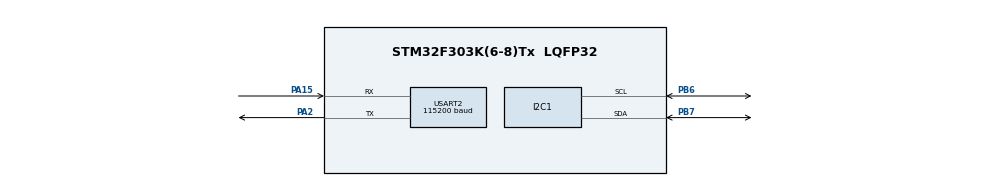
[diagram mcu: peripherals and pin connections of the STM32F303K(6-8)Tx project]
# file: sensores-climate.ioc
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Dma.Request0=USART2_RX
Dma.Request1=USART2_TX
Dma.USART2_RX.0.Direction=DMA_PERIPH_TO_MEMORY
Dma.USART2_RX.0.Instance=DMA1_Channel6
Dma.USART2_RX.0.MemDataAlignment=DMA_MDATAALIGN_BYTE
Dma.USART2_RX.0.MemInc=DMA_MINC_ENABLE
Dma.USART2_RX.0.Mode=DMA_NORMAL
Dma.USART2_RX.0.PeriphDataAlignment=DMA_PDATAALIGN_BYTE
Dma.USART2_RX.0.PeriphInc=DMA_PINC_DISABLE
Dma.USART2_RX.0.Priority=DMA_PRIORITY_MEDIUM
Dma.USART2_TX.1.Direction=DMA_MEMORY_TO_PERIPH
Dma.USART2_TX.1.Instance=DMA1_Channel7
Dma.USART2_TX.1.MemDataAlignment=DMA_MDATAALIGN_BYTE
Dma.USART2_TX.1.MemInc=DMA_MINC_ENABLE
Dma.USART2_TX.1.Mode=DMA_NORMAL
Dma.USART2_TX.1.PeriphDataAlignment=DMA_PDATAALIGN_BYTE
Dma.USART2_TX.1.PeriphInc=DMA_PINC_DISABLE
Dma.USART2_TX.1.Priority=DMA_PRIORITY_MEDIUM
I2C1.Timing=0x00201D2B
Mcu.Family=STM32F3
Mcu.Name=STM32F303K(6-8)Tx
Mcu.Package=LQFP32
NVIC.DMA1_Channel6_IRQn=true\:0\:0\:false\:false\:true\:false\:true\:true
NVIC.DMA1_Channel7_IRQn=true\:0\:0\:false\:false\:true\:false\:true\:true
NVIC.I2C1_EV_IRQn=true\:0\:0\:false\:false\:true\:true\:true\:true
NVIC.PriorityGroup=NVIC_PRIORITYGROUP_4
PA13.Mode=Serial_Wire
PA13.Signal=SYS_JTMS-SWDIO
PA14.Mode=Serial_Wire
PA14.Signal=SYS_JTCK-SWCLK
PA15.Mode=Asynchronous
PA15.Signal=USART2_RX
PA2.Mode=Asynchronous
PA2.Signal=USART2_TX
PB6.Mode=I2C
PB6.Signal=I2C1_SCL
PB7.Mode=I2C
PB7.Signal=I2C1_SDA
ProjectManager.HeapSize=0x200
ProjectManager.StackSize=0x400
ProjectManager.TargetToolchain=STM32CubeIDE
RCC.AHBFreq_Value=8000000
RCC.APB1Freq_Value=8000000
RCC.APB2Freq_Value=8000000
RCC.CortexFreq_Value=8000000
RCC.HSE_VALUE=8000000
RCC.HSI_VALUE=8000000
RCC.SYSCLKFreq_VALUE=8000000
USART2.BaudRate=115200
USART2.VirtualMode-Asynchronous=VM_ASYNC
board=custom

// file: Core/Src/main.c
/* USER CODE BEGIN Header */
/**
  ******************************************************************************
  * @file           : main.c
  * @brief          : Main program body
  ******************************************************************************
  * @attention
  *
  * Copyright (c) 2024 STMicroelectronics.
  * All rights reserved.
  *
  * This software is licensed under terms that can be found in the LICENSE file
  * in the root directory of this software component.
  * If no LICENSE file comes with this software, it is provided AS-IS.
  *
  ******************************************************************************
  */
/* USER CODE END Header */
#include "main.h"
#include "dma.h"
#include "i2c.h"
#include "usart.h"
#include "gpio.h"
#include "HTS221.h"
#include "LPS25HB.h"

/* USER CODE BEGIN PV */
float temperature;
float humidity;
float pressure;
float refference_pressure;
/* USER CODE END PV */

void SystemClock_Config(void);

#include <math.h>

#define SEA_LEVEL_PRESSURE 101325 // Pa, standard sea level pressure

// Function to calculate altitude based on pressure
float calculateAltitude(float pressure) {
    return (44330.0 * (1.0 - pow((pressure / SEA_LEVEL_PRESSURE), 0.1903)));
}

int main(void)
{

  /* MCU Configuration--------------------------------------------------------*/

  /* Reset of all peripherals, Initializes the Flash interface and the Systick. */
  LL_APB2_GRP1_EnableClock(LL_APB2_GRP1_PERIPH_SYSCFG);
  LL_APB1_GRP1_EnableClock(LL_APB1_GRP1_PERIPH_PWR);

  /* System interrupt init*/
  NVIC_SetPriorityGrouping(NVIC_PRIORITYGROUP_4);

  /* SysTick_IRQn interrupt configuration */
  NVIC_SetPriority(SysTick_IRQn, NVIC_EncodePriority(NVIC_GetPriorityGrouping(),15, 0));

  /* Configure the system clock */
  SystemClock_Config();

  /* Initialize all configured peripherals */
  MX_GPIO_Init();
  MX_DMA_Init();
  MX_I2C1_Init();
  MX_USART2_UART_Init();
  /* USER CODE BEGIN 2 */

  HTS221_init();
  LPS25HB_init();

  char tx_data[120];
  const char tx_message[] = "Temperature: %2.1f°C, Humidity: %.0f%%, Altitude: %.2f m, Pressure: %.2f Pa\r\n";
  //uint8_t tx_data[120];
  LL_mDelay(10);
  LPS25HB_get_pressure(&refference_pressure); // Reference pressure at the start for altitude comparison

  while (1) {
          HTS221_get_temperature(&temperature);
          HTS221_get_humidity(&humidity);
          LPS25HB_get_pressure(&pressure);
          float altitude = 44330.0 * (1.0 - pow(pressure / refference_pressure, 1 / 5.255));
          uint8_t tx_data_len = (uint8_t)sprintf(tx_data, tx_message, temperature, humidity, altitude, pressure);
          USART2_PutBuffer((uint8_t*)tx_data, tx_data_len);
          LL_mDelay(500);
      }

  /* USER CODE END 3 */
}

void SystemClock_Config(void)
{
  LL_FLASH_SetLatency(LL_FLASH_LATENCY_0);
  while(LL_FLASH_GetLatency()!= LL_FLASH_LATENCY_0)
  {
  }
  LL_RCC_HSI_Enable();

   /* Wait till HSI is ready */
  while(LL_RCC_HSI_IsReady() != 1)
  {

  }
  LL_RCC_HSI_SetCalibTrimming(16);
  LL_RCC_SetAHBPrescaler(LL_RCC_SYSCLK_DIV_1);
  LL_RCC_SetAPB1Prescaler(LL_RCC_APB1_DIV_1);
  LL_RCC_SetAPB2Prescaler(LL_RCC_APB2_DIV_1);
  LL_RCC_SetSysClkSource(LL_RCC_SYS_CLKSOURCE_HSI);

   /* Wait till System clock is ready */
  while(LL_RCC_GetSysClkSource() != LL_RCC_SYS_CLKSOURCE_STATUS_HSI)
  {

  }
  LL_Init1msTick(8000000);
  LL_SetSystemCoreClock(8000000);
  LL_RCC_SetI2CClockSource(LL_RCC_I2C1_CLKSOURCE_HSI);
}

void Error_Handler(void)
{
  __disable_irq();
  while (1)
  {
  }
}
